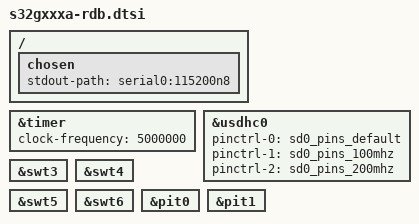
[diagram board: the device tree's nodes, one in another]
// SPDX-License-Identifier: GPL-2.0-or-later OR MIT
/*
 * Copyright (c) 2021 SUSE LLC
 * Copyright 2019-2023 NXP
 */

#include "s32g-nxp-flash-macronix.dtsi"

/ {
	chosen {
		stdout-path = "serial0:115200n8";
	};
};

&timer {
	clock-frequency = <5000000>;
};

&usdhc0 {
	pinctrl-names = "default", "state_100mhz", "state_200mhz";
	pinctrl-0 = <&sd0_pins_default>;
	pinctrl-1 = <&sd0_pins_100mhz>;
	pinctrl-2 = <&sd0_pins_200mhz>;
	status = "okay";
};

&swt3 {
	status = "okay";
};

&swt4 {
	status = "okay";
};

&swt5 {
	status = "okay";
};

&swt6 {
	status = "okay";
};

&pit0 {
	status = "okay";
};

&pit1 {
	status = "okay";
};
